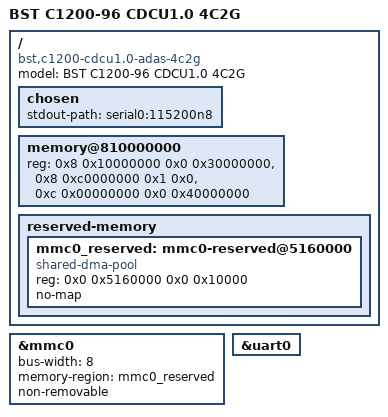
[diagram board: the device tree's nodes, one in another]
// SPDX-License-Identifier: GPL-2.0
/dts-v1/;

#include "bstc1200.dtsi"

/ {
	model = "BST C1200-96 CDCU1.0 4C2G";
	compatible = "bst,c1200-cdcu1.0-adas-4c2g", "bst,c1200";

	chosen {
		stdout-path = "serial0:115200n8";
	};

	memory@810000000 {
		device_type = "memory";
		reg = <0x8 0x10000000 0x0 0x30000000>,
		      <0x8 0xc0000000 0x1 0x0>,
		      <0xc 0x00000000 0x0 0x40000000>;
	};

	reserved-memory {
		#address-cells = <2>;
		#size-cells = <2>;
		ranges;

		mmc0_reserved: mmc0-reserved@5160000 {
			compatible = "shared-dma-pool";
			reg = <0x0 0x5160000 0x0 0x10000>;
			no-map;
		};
	};
};

&mmc0 {
	bus-width = <8>;
	memory-region = <&mmc0_reserved>;
	non-removable;
	status = "okay";
};

&uart0 {
	status = "okay";
};
